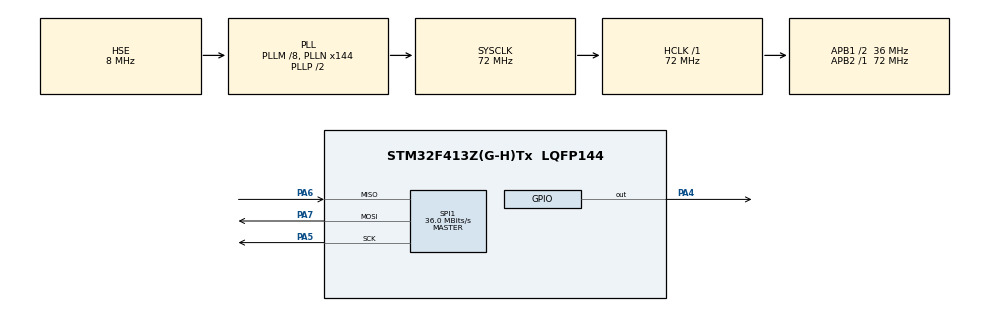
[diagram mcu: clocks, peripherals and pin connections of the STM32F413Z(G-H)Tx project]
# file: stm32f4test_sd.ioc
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FATFS._MAX_SS=4096
FATFS._USE_LFN=1
Mcu.Family=STM32F4
Mcu.Name=STM32F413Z(G-H)Tx
Mcu.Package=LQFP144
NVIC.PriorityGroup=NVIC_PRIORITYGROUP_4
PA4.Signal=GPIO_Output
PA5.Mode=Full_Duplex_Master
PA5.Signal=SPI1_SCK
PA6.Mode=Full_Duplex_Master
PA6.Signal=SPI1_MISO
PA7.Mode=Full_Duplex_Master
PA7.Signal=SPI1_MOSI
PH0\ -\ OSC_IN.Mode=HSE-External-Oscillator
PH0\ -\ OSC_IN.Signal=RCC_OSC_IN
PH1\ -\ OSC_OUT.Mode=HSE-External-Oscillator
PH1\ -\ OSC_OUT.Signal=RCC_OSC_OUT
ProjectManager.HeapSize=0x200
ProjectManager.StackSize=0x400
ProjectManager.TargetToolchain=STM32CubeIDE
RCC.AHBFreq_Value=72000000
RCC.APB1CLKDivider=RCC_HCLK_DIV2
RCC.APB1Freq_Value=36000000
RCC.APB1TimFreq_Value=72000000
RCC.APB2Freq_Value=72000000
RCC.APB2TimFreq_Value=72000000
RCC.CortexFreq_Value=72000000
RCC.HCLKFreq_Value=72000000
RCC.HSE_VALUE=8000000
RCC.PLLM=8
RCC.PLLN=144
RCC.PLLSourceVirtual=RCC_PLLSOURCE_HSE
RCC.SYSCLKFreq_VALUE=72000000
RCC.SYSCLKSource=RCC_SYSCLKSOURCE_PLLCLK
RCC.USBFreq_Value=72000000
RCC.VCOOutputFreq_Value=144000000
SPI1.BaudRatePrescaler=SPI_BAUDRATEPRESCALER_2
SPI1.CalculateBaudRate=36.0 MBits/s
SPI1.Direction=SPI_DIRECTION_2LINES
SPI1.Mode=SPI_MODE_MASTER
SPI1.VirtualType=VM_MASTER
VP_FATFS_VS_Generic.Mode=User_defined
board=custom

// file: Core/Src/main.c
/* USER CODE BEGIN Header */
/**
  ******************************************************************************
  * @file           : main.c
  * @brief          : Main program body
  ******************************************************************************
  * @attention
  *
  * <h2><center>&copy; Copyright (c) 2020 STMicroelectronics.
  * All rights reserved.</center></h2>
  *
  * This software component is licensed by ST under Ultimate Liberty license
  * SLA0044, the "License"; You may not use this file except in compliance with
  * the License. You may obtain a copy of the License at:
  *                             www.st.com/SLA0044
  *
  ******************************************************************************
  */
/* USER CODE END Header */

#include "main.h"
#include "fatfs.h"
#include "stm32f4xx_hal.h"

SPI_HandleTypeDef hspi1;

/* USER CODE BEGIN PV */
FATFS fs;
FATFS *pfs;
FIL fil;
FRESULT fres;
DWORD fre_clust;
uint32_t total, free1;
char buffer[100];
/* USER CODE END PV */

void SystemClock_Config(void);
static void MX_GPIO_Init(void);
static void MX_SPI1_Init(void);

int main(void)
{

  /* MCU Configuration--------------------------------------------------------*/

  /* Reset of all peripherals, Initializes the Flash interface and the Systick. */
  HAL_Init();

  /* Configure the system clock */
  SystemClock_Config();

  /* Initialize all configured peripherals */
  MX_GPIO_Init();
  MX_SPI1_Init();
  MX_FATFS_Init();

  // USER CODE BEGIN 2

  if(f_mount(&fs, "", 0) != FR_OK)
     _Error_Handler(__FILE__, __LINE__);
  else  fres = f_mount(&fs, "", 0);

   // Open file to write
   if(f_open(&fs, "out.txt",  FA_READ | FA_WRITE) != FR_OK)
     _Error_Handler(__FILE__, __LINE__);
   else fres = f_open(&fil, "second.py", FA_OPEN_ALWAYS | FA_READ | FA_WRITE);
   // Check free space
   if(f_getfree("", &fre_clust, &pfs) != FR_OK)
     _Error_Handler(__FILE__, __LINE__);

   total = (uint32_t)((pfs->n_fatent - 2) * pfs->csize * 0.5);
   free1 = (uint32_t)(fre_clust * pfs->csize * 0.5);

   // Free space is less than 1kb
   if(free1 < 1)
     _Error_Handler(__FILE__, __LINE__);

   //Writing text
   f_puts("SAKET\n", &fil);
   f_puts("KIRANGE!!!", &fil);

   // Close file
   if(f_close(&fil) != FR_OK)
     _Error_Handler(__FILE__, __LINE__);

   // Open file to read
   if(f_open(&fil, "second.py", FA_READ) != FR_OK)
     _Error_Handler(__FILE__, __LINE__);

   while(f_gets(buffer, sizeof(buffer), &fil))
   {
     //printf("%s", buffer);
   }

   // Close file
   if(f_close(&fil) != FR_OK)
     _Error_Handler(__FILE__, __LINE__);

   // Unmount SDCARD
   if(f_mount(NULL, "", 1) != FR_OK)
     _Error_Handler(__FILE__, __LINE__);

/*

  fres = f_mount(&fs, "", 0);
 // f_getfree("", &fre_clust, &pfs);
  //total = (uint32_t)((pfs->n_fatent - 2) * pfs->csize * 0.5);
  fres = f_open(&fil, "message.txt", FA_READ | FA_READ | FA_WRITE);
  //if (fres) return (int)fres;
  fres = f_puts("This data is from the First FILE\n\n", &fil);
  f_close(&fil);

*/
  /* USER CODE END 2 */

  /* Infinite loop */
  while (1)
  {

  }
}

void SystemClock_Config(void)
{
  RCC_OscInitTypeDef RCC_OscInitStruct = {0};
  RCC_ClkInitTypeDef RCC_ClkInitStruct = {0};

  /** Configure the main internal regulator output voltage
  */
  __HAL_RCC_PWR_CLK_ENABLE();
  __HAL_PWR_VOLTAGESCALING_CONFIG(PWR_REGULATOR_VOLTAGE_SCALE1);
  /** Initializes the CPU, AHB and APB busses clocks
  */
  RCC_OscInitStruct.OscillatorType = RCC_OSCILLATORTYPE_HSE;
  RCC_OscInitStruct.HSEState = RCC_HSE_ON;
  RCC_OscInitStruct.PLL.PLLState = RCC_PLL_ON;
  RCC_OscInitStruct.PLL.PLLSource = RCC_PLLSOURCE_HSE;
  RCC_OscInitStruct.PLL.PLLM = 8;
  RCC_OscInitStruct.PLL.PLLN = 144;
  RCC_OscInitStruct.PLL.PLLP = RCC_PLLP_DIV2;
  RCC_OscInitStruct.PLL.PLLQ = 2;
  RCC_OscInitStruct.PLL.PLLR = 2;
  if (HAL_RCC_OscConfig(&RCC_OscInitStruct) != HAL_OK)
  {
    _Error_Handler(__FILE__, __LINE__);
  }
  /** Initializes the CPU, AHB and APB busses clocks
  */
  RCC_ClkInitStruct.ClockType = RCC_CLOCKTYPE_HCLK|RCC_CLOCKTYPE_SYSCLK
                              |RCC_CLOCKTYPE_PCLK1|RCC_CLOCKTYPE_PCLK2;
  RCC_ClkInitStruct.SYSCLKSource = RCC_SYSCLKSOURCE_PLLCLK;
  RCC_ClkInitStruct.AHBCLKDivider = RCC_SYSCLK_DIV1;
  RCC_ClkInitStruct.APB1CLKDivider = RCC_HCLK_DIV2;
  RCC_ClkInitStruct.APB2CLKDivider = RCC_HCLK_DIV1;

  if (HAL_RCC_ClockConfig(&RCC_ClkInitStruct, FLASH_LATENCY_2) != HAL_OK)
  {
    _Error_Handler(__FILE__, __LINE__);
  }
}

static void MX_SPI1_Init(void)
{

  /* SPI1 parameter configuration*/
  hspi1.Instance = SPI1;
  hspi1.Init.Mode = SPI_MODE_MASTER;
  hspi1.Init.Direction = SPI_DIRECTION_2LINES;
  hspi1.Init.DataSize = SPI_DATASIZE_8BIT;
  hspi1.Init.CLKPolarity = SPI_POLARITY_LOW;
  hspi1.Init.CLKPhase = SPI_PHASE_1EDGE;
  hspi1.Init.NSS = SPI_NSS_SOFT;
  hspi1.Init.BaudRatePrescaler = SPI_BAUDRATEPRESCALER_2;
  hspi1.Init.FirstBit = SPI_FIRSTBIT_MSB;
  hspi1.Init.TIMode = SPI_TIMODE_DISABLE;
  hspi1.Init.CRCCalculation = SPI_CRCCALCULATION_DISABLE;
  hspi1.Init.CRCPolynomial = 10;
  if (HAL_SPI_Init(&hspi1) != HAL_OK)
  {
    _Error_Handler(__FILE__, __LINE__);
  }

}

static void MX_GPIO_Init(void)
{
  GPIO_InitTypeDef GPIO_InitStruct = {0};

  /* GPIO Ports Clock Enable */
  __HAL_RCC_GPIOH_CLK_ENABLE();
  __HAL_RCC_GPIOA_CLK_ENABLE();

  /*Configure GPIO pin Output Level */
  HAL_GPIO_WritePin(GPIOA, GPIO_PIN_4, GPIO_PIN_RESET);

  /*Configure GPIO pin : PA4 */
  GPIO_InitStruct.Pin = GPIO_PIN_4;
  GPIO_InitStruct.Mode = GPIO_MODE_OUTPUT_PP;
  GPIO_InitStruct.Pull = GPIO_NOPULL;
  GPIO_InitStruct.Speed = GPIO_SPEED_FREQ_LOW;
  HAL_GPIO_Init(GPIOA, &GPIO_InitStruct);

}

void _Error_Handler(char *file, int line)
{
  while(1)
  {
  }
}

/************************ (C) COPYRIGHT STMicroelectronics *****END OF FILE****/
